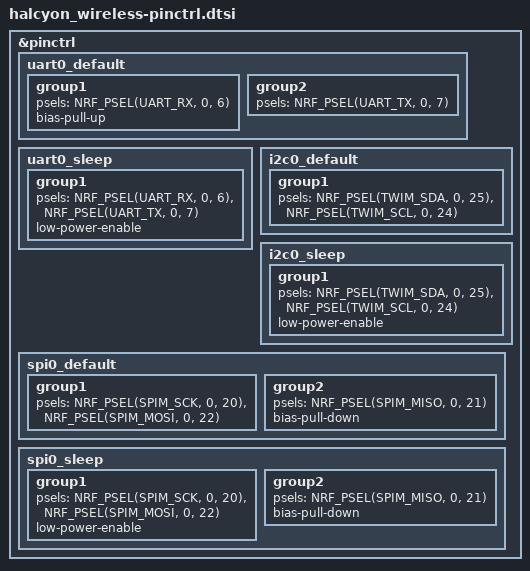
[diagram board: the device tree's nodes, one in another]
/*
 * Copyright (c) 2022 The ZMK Contributors
 * Copyright (c) 2026 Splitkb.com
 *
 * SPDX-License-Identifier: MIT
 */

&pinctrl {
	uart0_default: uart0_default {
        group1 {
            psels = <NRF_PSEL(UART_RX, 0, 6)>;
            bias-pull-up;
        };
        group2 {
            psels = <NRF_PSEL(UART_TX, 0, 7)>;
        };
    };

    uart0_sleep: uart0_sleep {
        group1 {
            psels = <NRF_PSEL(UART_RX, 0, 6)>,
                <NRF_PSEL(UART_TX, 0, 7)>;
            low-power-enable;
        };
    };

	i2c0_default: i2c0_default {
        group1 {
            psels = <NRF_PSEL(TWIM_SDA, 0, 25)>,
                <NRF_PSEL(TWIM_SCL, 0, 24)>;
        };
    };

	i2c0_sleep: i2c0_sleep {
        group1 {
            psels = <NRF_PSEL(TWIM_SDA, 0, 25)>,
                <NRF_PSEL(TWIM_SCL, 0, 24)>;
            low-power-enable;
        };
    };

	spi0_default: spi0_default {
        group1 {
            psels = <NRF_PSEL(SPIM_SCK, 0, 20)>,
                <NRF_PSEL(SPIM_MOSI, 0, 22)>;
        };
        group2 {
            psels = <NRF_PSEL(SPIM_MISO, 0, 21)>;
            bias-pull-down;
        };
    };

	spi0_sleep: spi0_sleep {
        group1 {
            psels = <NRF_PSEL(SPIM_SCK, 0, 20)>,
                <NRF_PSEL(SPIM_MOSI, 0, 22)>;
            low-power-enable;
        };
        group2 {
            psels = <NRF_PSEL(SPIM_MISO, 0, 21)>;
            bias-pull-down;
        };
    };    
};
